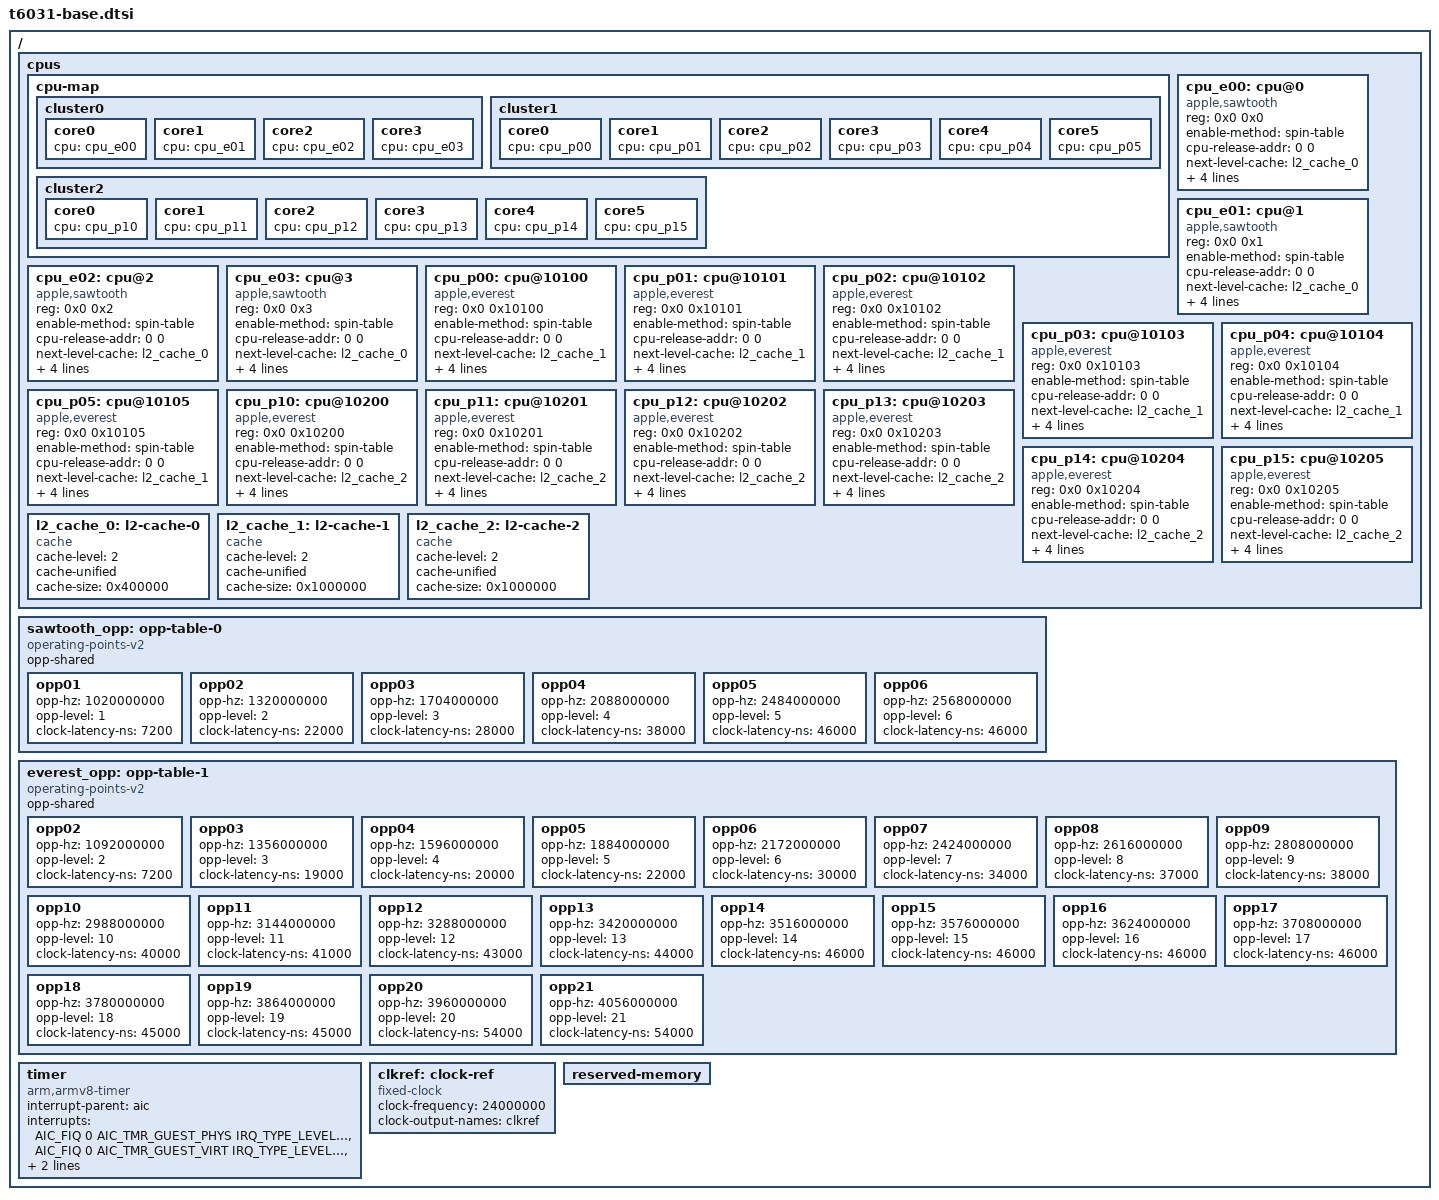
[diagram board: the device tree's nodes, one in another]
// SPDX-License-Identifier: GPL-2.0+ OR MIT
/*
 * Nodes common for T6031, T6032 and T6034 family SoCs (M3 Max/Ultra)
 *
 * Other names: H15J, H15S, "Palma"
 *
 * Copyright The Asahi Linux Contributors
 */

/ {
	#address-cells = <2>;
	#size-cells = <2>;

	cpus {
		#address-cells = <2>;
		#size-cells = <0>;

		cpu-map {
			cluster0 {
				core0 {
					cpu = <&cpu_e00>;
				};
				core1 {
					cpu = <&cpu_e01>;
				};
				core2 {
					cpu = <&cpu_e02>;
				};
				core3 {
					cpu = <&cpu_e03>;
				};
			};

			cluster1 {
				core0 {
					cpu = <&cpu_p00>;
				};
				core1 {
					cpu = <&cpu_p01>;
				};
				core2 {
					cpu = <&cpu_p02>;
				};
				core3 {
					cpu = <&cpu_p03>;
				};
				core4 {
					cpu = <&cpu_p04>;
				};
				core5 {
					cpu = <&cpu_p05>;
				};
			};

			cluster2 {
				core0 {
					cpu = <&cpu_p10>;
				};
				core1 {
					cpu = <&cpu_p11>;
				};
				core2 {
					cpu = <&cpu_p12>;
				};
				core3 {
					cpu = <&cpu_p13>;
				};
				core4 {
					cpu = <&cpu_p14>;
				};
				core5 {
					cpu = <&cpu_p15>;
				};
			};
		};

		cpu_e00: cpu@0 {
			compatible = "apple,sawtooth";
			device_type = "cpu";
			reg = <0x0 0x0>;
			enable-method = "spin-table";
			cpu-release-addr = <0 0>; /* to be filled by loader */
			next-level-cache = <&l2_cache_0>;
			i-cache-size = <0x20000>;
			d-cache-size = <0x10000>;
			operating-points-v2 = <&sawtooth_opp>;
			performance-domains = <&cpufreq_e>;
		};

		cpu_e01: cpu@1 {
			compatible = "apple,sawtooth";
			device_type = "cpu";
			reg = <0x0 0x1>;
			enable-method = "spin-table";
			cpu-release-addr = <0 0>; /* to be filled by loader */
			next-level-cache = <&l2_cache_0>;
			i-cache-size = <0x20000>;
			d-cache-size = <0x10000>;
			operating-points-v2 = <&sawtooth_opp>;
			performance-domains = <&cpufreq_e>;
		};

		cpu_e02: cpu@2 {
			compatible = "apple,sawtooth";
			device_type = "cpu";
			reg = <0x0 0x2>;
			enable-method = "spin-table";
			cpu-release-addr = <0 0>; /* to be filled by loader */
			next-level-cache = <&l2_cache_0>;
			i-cache-size = <0x20000>;
			d-cache-size = <0x10000>;
			operating-points-v2 = <&sawtooth_opp>;
			performance-domains = <&cpufreq_e>;
		};

		cpu_e03: cpu@3 {
			compatible = "apple,sawtooth";
			device_type = "cpu";
			reg = <0x0 0x3>;
			enable-method = "spin-table";
			cpu-release-addr = <0 0>; /* to be filled by loader */
			next-level-cache = <&l2_cache_0>;
			i-cache-size = <0x20000>;
			d-cache-size = <0x10000>;
			operating-points-v2 = <&sawtooth_opp>;
			performance-domains = <&cpufreq_e>;
		};

		cpu_p00: cpu@10100 {
			compatible = "apple,everest";
			device_type = "cpu";
			reg = <0x0 0x10100>;
			enable-method = "spin-table";
			cpu-release-addr = <0 0>; /* To be filled by loader */
			next-level-cache = <&l2_cache_1>;
			i-cache-size = <0x30000>;
			d-cache-size = <0x20000>;
			operating-points-v2 = <&everest_opp>;
			performance-domains = <&cpufreq_p0>;
		};

		cpu_p01: cpu@10101 {
			compatible = "apple,everest";
			device_type = "cpu";
			reg = <0x0 0x10101>;
			enable-method = "spin-table";
			cpu-release-addr = <0 0>; /* To be filled by loader */
			next-level-cache = <&l2_cache_1>;
			i-cache-size = <0x30000>;
			d-cache-size = <0x20000>;
			operating-points-v2 = <&everest_opp>;
			performance-domains = <&cpufreq_p0>;
		};

		cpu_p02: cpu@10102 {
			compatible = "apple,everest";
			device_type = "cpu";
			reg = <0x0 0x10102>;
			enable-method = "spin-table";
			cpu-release-addr = <0 0>; /* To be filled by loader */
			next-level-cache = <&l2_cache_1>;
			i-cache-size = <0x30000>;
			d-cache-size = <0x20000>;
			operating-points-v2 = <&everest_opp>;
			performance-domains = <&cpufreq_p0>;
		};

		cpu_p03: cpu@10103 {
			compatible = "apple,everest";
			device_type = "cpu";
			reg = <0x0 0x10103>;
			enable-method = "spin-table";
			cpu-release-addr = <0 0>; /* To be filled by loader */
			next-level-cache = <&l2_cache_1>;
			i-cache-size = <0x30000>;
			d-cache-size = <0x20000>;
			operating-points-v2 = <&everest_opp>;
			performance-domains = <&cpufreq_p0>;
		};

		cpu_p04: cpu@10104 {
			compatible = "apple,everest";
			device_type = "cpu";
			reg = <0x0 0x10104>;
			enable-method = "spin-table";
			cpu-release-addr = <0 0>; /* To be filled by loader */
			next-level-cache = <&l2_cache_1>;
			i-cache-size = <0x30000>;
			d-cache-size = <0x20000>;
			operating-points-v2 = <&everest_opp>;
			performance-domains = <&cpufreq_p0>;
		};

		cpu_p05: cpu@10105 {
			compatible = "apple,everest";
			device_type = "cpu";
			reg = <0x0 0x10105>;
			enable-method = "spin-table";
			cpu-release-addr = <0 0>; /* To be filled by loader */
			next-level-cache = <&l2_cache_1>;
			i-cache-size = <0x30000>;
			d-cache-size = <0x20000>;
			operating-points-v2 = <&everest_opp>;
			performance-domains = <&cpufreq_p0>;
		};

		cpu_p10: cpu@10200 {
			compatible = "apple,everest";
			device_type = "cpu";
			reg = <0x0 0x10200>;
			enable-method = "spin-table";
			cpu-release-addr = <0 0>; /* To be filled by loader */
			next-level-cache = <&l2_cache_2>;
			i-cache-size = <0x30000>;
			d-cache-size = <0x20000>;
			operating-points-v2 = <&everest_opp>;
			performance-domains = <&cpufreq_p1>;
		};

		cpu_p11: cpu@10201 {
			compatible = "apple,everest";
			device_type = "cpu";
			reg = <0x0 0x10201>;
			enable-method = "spin-table";
			cpu-release-addr = <0 0>; /* To be filled by loader */
			next-level-cache = <&l2_cache_2>;
			i-cache-size = <0x30000>;
			d-cache-size = <0x20000>;
			operating-points-v2 = <&everest_opp>;
			performance-domains = <&cpufreq_p1>;
		};

		cpu_p12: cpu@10202 {
			compatible = "apple,everest";
			device_type = "cpu";
			reg = <0x0 0x10202>;
			enable-method = "spin-table";
			cpu-release-addr = <0 0>; /* To be filled by loader */
			next-level-cache = <&l2_cache_2>;
			i-cache-size = <0x30000>;
			d-cache-size = <0x20000>;
			operating-points-v2 = <&everest_opp>;
			performance-domains = <&cpufreq_p1>;
		};

		cpu_p13: cpu@10203 {
			compatible = "apple,everest";
			device_type = "cpu";
			reg = <0x0 0x10203>;
			enable-method = "spin-table";
			cpu-release-addr = <0 0>; /* To be filled by loader */
			next-level-cache = <&l2_cache_2>;
			i-cache-size = <0x30000>;
			d-cache-size = <0x20000>;
			operating-points-v2 = <&everest_opp>;
			performance-domains = <&cpufreq_p1>;
		};

		cpu_p14: cpu@10204 {
			compatible = "apple,everest";
			device_type = "cpu";
			reg = <0x0 0x10204>;
			enable-method = "spin-table";
			cpu-release-addr = <0 0>; /* To be filled by loader */
			next-level-cache = <&l2_cache_2>;
			i-cache-size = <0x30000>;
			d-cache-size = <0x20000>;
			operating-points-v2 = <&everest_opp>;
			performance-domains = <&cpufreq_p1>;
		};

		cpu_p15: cpu@10205 {
			compatible = "apple,everest";
			device_type = "cpu";
			reg = <0x0 0x10205>;
			enable-method = "spin-table";
			cpu-release-addr = <0 0>; /* To be filled by loader */
			next-level-cache = <&l2_cache_2>;
			i-cache-size = <0x30000>;
			d-cache-size = <0x20000>;
			operating-points-v2 = <&everest_opp>;
			performance-domains = <&cpufreq_p1>;
		};

		l2_cache_0: l2-cache-0 {
			compatible = "cache";
			cache-level = <2>;
			cache-unified;
			cache-size = <0x400000>;
		};

		l2_cache_1: l2-cache-1 {
			compatible = "cache";
			cache-level = <2>;
			cache-unified;
			cache-size = <0x1000000>;
		};

		l2_cache_2: l2-cache-2 {
			compatible = "cache";
			cache-level = <2>;
			cache-unified;
			cache-size = <0x1000000>;
		};
	};

	sawtooth_opp: opp-table-0 {
		compatible = "operating-points-v2";
		opp-shared;

		opp01 {
			opp-hz = /bits/ 64 <1020000000>;
			opp-level = <1>;
			clock-latency-ns = <7200>;
		};
		opp02 {
			opp-hz = /bits/ 64 <1320000000>;
			opp-level = <2>;
			clock-latency-ns = <22000>;
		};
		opp03 {
			opp-hz = /bits/ 64 <1704000000>;
			opp-level = <3>;
			clock-latency-ns = <28000>;
		};
		opp04 {
			opp-hz = /bits/ 64 <2088000000>;
			opp-level = <4>;
			clock-latency-ns = <38000>;
		};
		opp05 {
			opp-hz = /bits/ 64 <2484000000>;
			opp-level = <5>;
			clock-latency-ns = <46000>;
		};
		opp06 {
			opp-hz = /bits/ 64 <2568000000>;
			opp-level = <6>;
			clock-latency-ns = <46000>;
		};
	};

	everest_opp: opp-table-1 {
		compatible = "operating-points-v2";
		opp-shared;

		/* pstate #1 is a dummy clone of #2 */
		opp02 {
			opp-hz = /bits/ 64 <1092000000>;
			opp-level = <2>;
			clock-latency-ns = <7200>;
		};
		opp03 {
			opp-hz = /bits/ 64 <1356000000>;
			opp-level = <3>;
			clock-latency-ns = <19000>;
		};
		opp04 {
			opp-hz = /bits/ 64 <1596000000>;
			opp-level = <4>;
			clock-latency-ns = <20000>;
		};
		opp05 {
			opp-hz = /bits/ 64 <1884000000>;
			opp-level = <5>;
			clock-latency-ns = <22000>;
		};
		opp06 {
			opp-hz = /bits/ 64 <2172000000>;
			opp-level = <6>;
			clock-latency-ns = <30000>;
		};
		opp07 {
			opp-hz = /bits/ 64 <2424000000>;
			opp-level = <7>;
			clock-latency-ns = <34000>;
		};
		opp08 {
			opp-hz = /bits/ 64 <2616000000>;
			opp-level = <8>;
			clock-latency-ns = <37000>;
		};
		opp09 {
			opp-hz = /bits/ 64 <2808000000>;
			opp-level = <9>;
			clock-latency-ns = <38000>;
		};
		opp10 {
			opp-hz = /bits/ 64 <2988000000>;
			opp-level = <10>;
			clock-latency-ns = <40000>;
		};
		opp11 {
			opp-hz = /bits/ 64 <3144000000>;
			opp-level = <11>;
			clock-latency-ns = <41000>;
		};
		opp12 {
			opp-hz = /bits/ 64 <3288000000>;
			opp-level = <12>;
			clock-latency-ns = <43000>;
		};
		opp13 {
			opp-hz = /bits/ 64 <3420000000>;
			opp-level = <13>;
			clock-latency-ns = <44000>;
		};
		opp14 {
			opp-hz = /bits/ 64 <3516000000>;
			opp-level = <14>;
			clock-latency-ns = <46000>;
		};
		opp15 {
			opp-hz = /bits/ 64 <3576000000>;
			opp-level = <15>;
			clock-latency-ns = <46000>;
		};
		opp16 {
			opp-hz = /bits/ 64 <3624000000>;
			opp-level = <16>;
			clock-latency-ns = <46000>;
		};
		opp17 {
			opp-hz = /bits/ 64 <3708000000>;
			opp-level = <17>;
			clock-latency-ns = <46000>;
		};
		opp18 {
			opp-hz = /bits/ 64 <3780000000>;
			opp-level = <18>;
			clock-latency-ns = <45000>;
		};
		opp19 {
			opp-hz = /bits/ 64 <3864000000>;
			opp-level = <19>;
			clock-latency-ns = <45000>;
		};
		opp20 {
			opp-hz = /bits/ 64 <3960000000>;
			opp-level = <20>;
			clock-latency-ns = <54000>;
		};
		opp21 {
			opp-hz = /bits/ 64 <4056000000>;
			opp-level = <21>;
			clock-latency-ns = <54000>;
		};
	};

	timer {
		compatible = "arm,armv8-timer";
		interrupt-parent = <&aic>;
		interrupt-names = "phys", "virt", "hyp-phys", "hyp-virt";
		interrupts = <AIC_FIQ 0 AIC_TMR_GUEST_PHYS IRQ_TYPE_LEVEL_HIGH>,
			     <AIC_FIQ 0 AIC_TMR_GUEST_VIRT IRQ_TYPE_LEVEL_HIGH>,
			     <AIC_FIQ 0 AIC_TMR_HV_PHYS IRQ_TYPE_LEVEL_HIGH>,
			     <AIC_FIQ 0 AIC_TMR_HV_VIRT IRQ_TYPE_LEVEL_HIGH>;
	};

	clkref: clock-ref {
		compatible = "fixed-clock";
		#clock-cells = <0>;
		clock-frequency = <24000000>;
		clock-output-names = "clkref";
	};

	reserved-memory {
		#address-cells = <2>;
		#size-cells = <2>;
		ranges;
	};
};
